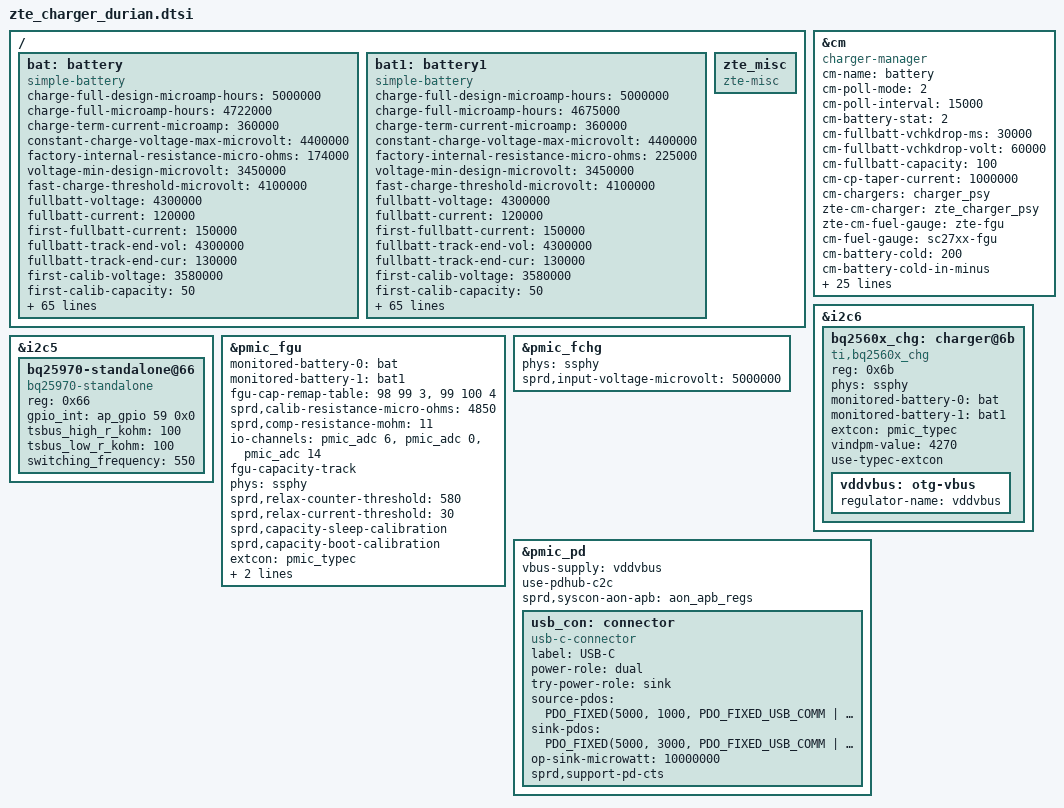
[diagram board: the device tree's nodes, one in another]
#include <dt-bindings/usb/pd.h>


/ {
	bat: battery {
		compatible = "simple-battery";
		status = "okay";
		charge-full-design-microamp-hours = <5000000>;
		/*Minimum Capacity 4870*0.9 = 4383 4870*0.94 = 4558 4870*0.95 = 4626 4870*0.96 = 4675,4870*0.98 = 4772  we use *0.98 */
		charge-full-microamp-hours = <4772000>;
		charge-term-current-microamp = <420000>;
		constant-charge-voltage-max-microvolt = <4400000>;
		factory-internal-resistance-micro-ohms = <225000>;
		voltage-min-design-microvolt = <3450000>;

		fast-charge-threshold-microvolt = <4100000>;
		fullbatt-voltage = <4300000>;
		fullbatt-current = <120000>;
		first-fullbatt-current = <150000>;
		fullbatt-track-end-vol = <4295000>;
		fullbatt-track-end-cur = <130000>;
		first-calib-voltage = <3580000>;
		first-calib-capacity = <50>;

		ir-cv-offset-microvolt = <100000>;
		ir-rc-micro-ohms = <20000>;
		ir-us-upper-limit-microvolt = <4500000>;

		batt-id-list = <300 10 390 20>;  /* kohm, scud / ningde / tianmao /guanyu*/
		ocv-capacity-celsius = <20>;
		ocv-capacity-table-0 = <4374000 100>, <4308000 95>, <4250000 90>,
					<4193000 85>, <4139000 80>, <4086000 75>,
					<4037000 70>, <3992000 65>, <3951000 60>,
					<3896000 55>, <3860000 50>, <3836000 45>,
					<3814000 40>, <3797000 35>, <3784000 30>,
					<3767000 25>, <3749000 20>, <3726000 15>,
					<3697000 10>, <3683000 5>, <3400000 0>;
		/* NTC 100k, Vref 1850mV, R pull-up 110K, R pull-down 1000k */
		voltage-temp-table = <1568441 750>, <1534549 800>, <1515014 850>,
					<1475819 900>, <1402274 950>, <1334550 1000>,
					<1222195 1050>, <1131821 1100>, <1035662 1150>,
					<936426 1200>, <837104 1250>, <740441 1300>,
					<648801 1350>, <563916 1400>, <486937 1450>,
					<418193 1500>, <357806 1550>, <305304 1600>,
					<260067 1650>, <221438 1700>, <188468 1750>;
		capacity-temp-table = <25 100>, <10 100>, <0 97>, <(-10) 89>, <(-20) 57>;
		resistance-temp-table = <25 100>, <10 332>, <0 507>, <(-10) 569>, <(-20) 675>;
		charge-sdp-current-microamp = <700000 500000>;
		charge-dcp-current-microamp = <2000000 3000000>;
		charge-cdp-current-microamp = <1500000 1500000>;
		charge-unknown-current-microamp = <1000000 1000000>;
		charge-fchg-current-microamp = <3400000 2000000>;
		charge-flash-current-microamp = <3400000 2700000>;

		cap-calib-energy-density-ocv-table = <3350000 3800000>, <4150000 4350000>;
		cap-track-energy-density-ocv-table = <3400000 3722000>;

		dcp-jeita-temp-table = <1000 1030 0 4400000>,
					<1050 1080 1400000 4400000>,
					<1100 1180 1400000 4400000>,
					<1450 1420 3400000 4400000>,
					<1550 1520 2400000 4100000>;
		sdp-jeita-temp-table = <1000 1030 0 4400000>,
					<1050 1080 1400000 4400000>,
					<1100 1180 1400000 4400000>,
					<1450 1420 3400000 4400000>,
					<1550 1520 2400000 4100000>;
		cdp-jeita-temp-table = <1000 1030 0 4400000>,
					<1050 1080 1400000 4400000>,
					<1100 1180 1400000 4400000>,
					<1450 1420 3400000 4400000>,
					<1550 1520 2400000 4100000>;
		unknown-jeita-temp-table = <1000 1030 0 4400000>,
					<1050 1080 1400000 4400000>,
					<1100 1180 1400000 4400000>,
					<1450 1420 3400000 4400000>,
					<1550 1520 2400000 4100000>;
		fchg-jeita-temp-table = <1000 1030 0 4400000>,
					<1050 1080 1400000 4400000>,
					<1100 1180 1400000 4400000>,
					<1450 1420 3400000 4400000>,
					<1550 1520 2400000 4100000>;
		flash-jeita-temp-table = <1000 1030 0 4400000>,
					<1050 1080 1400000 4400000>,
					<1100 1180 1400000 4400000>,
					<1450 1420 3400000 4400000>,
					<1550 1520 2400000 4100000>;
	};

	bat1: battery1 {
		compatible = "simple-battery";
		status = "okay";
		charge-full-design-microamp-hours = <5000000>;
		/*Minimum Capacity 4870*0.9 = 4383 4870*0.94 = 4558 4870*0.95 = 4626 4870*0.96 = 4675,4870*0.98 = 4772  we use *0.98 */
		charge-full-microamp-hours = <4772000>;
		charge-term-current-microamp = <420000>;
		constant-charge-voltage-max-microvolt = <4400000>;
		factory-internal-resistance-micro-ohms = <225000>;
		voltage-min-design-microvolt = <3450000>;

		fast-charge-threshold-microvolt = <4100000>;
		fullbatt-voltage = <4300000>;
		fullbatt-current = <120000>;
		first-fullbatt-current = <150000>;
		fullbatt-track-end-vol = <4295000>;
		fullbatt-track-end-cur = <130000>;
		first-calib-voltage = <3580000>;
		first-calib-capacity = <50>;

		ir-cv-offset-microvolt = <100000>;
		ir-rc-micro-ohms = <20000>;
		ir-us-upper-limit-microvolt = <4500000>;

		batt-id-list = <300 10 390 20>;  /* kohm, scud / ningde / tianmao /guanyu*/
		ocv-capacity-celsius = <20>;
		ocv-capacity-table-0 = <4374000 100>, <4308000 95>, <4250000 90>,
					<4193000 85>, <4139000 80>, <4086000 75>,
					<4037000 70>, <3992000 65>, <3951000 60>,
					<3896000 55>, <3860000 50>, <3836000 45>,
					<3814000 40>, <3797000 35>, <3784000 30>,
					<3767000 25>, <3749000 20>, <3726000 15>,
					<3697000 10>, <3683000 5>, <3400000 0>;
		/* NTC 100k, Vref 1850mV, R pull-up 110K, R pull-down 1000k */
		voltage-temp-table = <1568441 750>, <1534549 800>, <1515014 850>,
					<1475819 900>, <1402274 950>, <1334550 1000>,
					<1222195 1050>, <1131821 1100>, <1035662 1150>,
					<936426 1200>, <837104 1250>, <740441 1300>,
					<648801 1350>, <563916 1400>, <486937 1450>,
					<418193 1500>, <357806 1550>, <305304 1600>,
					<260067 1650>, <221438 1700>, <188468 1750>;
		capacity-temp-table = <25 100>, <10 100>, <0 97>, <(-10) 89>, <(-20) 57>;
		resistance-temp-table = <25 100>, <10 332>, <0 507>, <(-10) 569>, <(-20) 675>;
		charge-sdp-current-microamp = <700000 500000>;
		charge-dcp-current-microamp = <2000000 3000000>;
		charge-cdp-current-microamp = <1500000 1500000>;
		charge-unknown-current-microamp = <1000000 1000000>;
		charge-fchg-current-microamp = <3400000 2000000>;
		charge-flash-current-microamp = <3400000 2700000>;

		cap-calib-energy-density-ocv-table = <3350000 3800000>, <4150000 4350000>;
		cap-track-energy-density-ocv-table = <3400000 3722000>;

		dcp-jeita-temp-table = <1000 1030 0 4400000>,
					<1050 1080 1400000 4400000>,
					<1100 1180 1400000 4400000>,
					<1450 1420 3400000 4400000>,
					<1550 1520 2400000 4100000>;
		sdp-jeita-temp-table = <1000 1030 0 4400000>,
					<1050 1080 1400000 4400000>,
					<1100 1180 1400000 4400000>,
					<1450 1420 3400000 4400000>,
					<1550 1520 2400000 4100000>;
		cdp-jeita-temp-table = <1000 1030 0 4400000>,
					<1050 1080 1400000 4400000>,
					<1100 1180 1400000 4400000>,
					<1450 1420 3400000 4400000>,
					<1550 1520 2400000 4100000>;
		unknown-jeita-temp-table = <1000 1030 0 4400000>,
					<1050 1080 1400000 4400000>,
					<1100 1180 1400000 4400000>,
					<1450 1420 3400000 4400000>,
					<1550 1520 2400000 4100000>;
		fchg-jeita-temp-table = <1000 1030 0 4400000>,
					<1050 1080 1400000 4400000>,
					<1100 1180 1400000 4400000>,
					<1450 1420 3400000 4400000>,
					<1550 1520 2400000 4100000>;
		flash-jeita-temp-table = <1000 1030 0 4400000>,
					<1050 1080 1400000 4400000>,
					<1100 1180 1400000 4400000>,
					<1450 1420 3400000 4400000>,
					<1550 1520 2400000 4100000>;
	};




};

&bat {
	compatible = "simple-battery";
	status = "okay";
	charge-full-design-microamp-hours = <5000000>;
	/*Minimum Capacity 4870*0.9 = 4383 4870*0.94 = 4558 4870*0.95 = 4626 4870*0.96 = 4675,4870*0.98 = 4772  we use *0.98 */
	charge-full-microamp-hours = <4722000>;
	charge-term-current-microamp = <360000>;
	constant-charge-voltage-max-microvolt = <4400000>;
	factory-internal-resistance-micro-ohms = <174000>;
	voltage-min-design-microvolt = <3450000>;

	fast-charge-threshold-microvolt = <4100000>;
	fullbatt-voltage = <4300000>;
	fullbatt-current = <120000>;
	first-fullbatt-current = <150000>;
	fullbatt-track-end-vol = <4300000>;
	fullbatt-track-end-cur = <130000>;
	first-calib-voltage = <3580000>;
	first-calib-capacity = <50>;

	ir-cv-offset-microvolt = <100000>;
	ir-rc-micro-ohms = <20000>;
	ir-us-upper-limit-microvolt = <4500000>;

	batt-id-list = <180 51>;  /* kohm, tianmao/scud */
	ocv-capacity-celsius = <25>;
	ocv-capacity-table-0 = <4323000 100>, <4262000 95>, <4206000 90>,
				<4152000 85>, <4100000 80>, <4052000 75>,
				<4006000 70>, <3966000 65>, <3916000 60>,
				<3869000 55>, <3841000 50>, <3820000 45>,
				<3802000 40>, <3788000 35>, <3773000 30>,
				<3754000 25>, <3737000 20>, <3712000 15>,
				<3686000 10>, <3672000 5>, <3400000 0>;

	/* NTC 100k, Vref 1850mV, R pull-up 110K, R pull-down 1000k */
	voltage-temp-table = <1568441 750>, <1534549 800>, <1515014 850>,
				<1475819 900>, <1402274 950>, <1334550 1000>,
				<1222195 1050>, <1131821 1100>, <1035662 1150>,
				<936426 1200>, <837104 1250>, <740441 1300>,
				<648801 1350>, <563916 1400>, <486937 1450>,
				<418193 1500>, <357806 1550>, <305304 1600>,
				<260067 1650>, <221438 1700>, <188468 1750>;
	capacity-temp-table = <25 100>, <10 100>, <0 97>, <(-10) 90>, <(-20) 65>;
	resistance-temp-table = <25 100>, <10 195>, <0 610>, <(-10) 695>, <(-20) 809>;

	charge-sdp-current-microamp = <700000 500000>;
	charge-dcp-current-microamp = <4800000 2000000>;
	charge-cdp-current-microamp = <4800000 1500000>;
	charge-unknown-current-microamp = <1000000 1000000>;
	charge-fchg-current-microamp = <4800000 2000000>;
	charge-flash-current-microamp = <4800000 2000000>;

	cap-calib-energy-density-ocv-table = <3350000 3800000>, <4150000 4350000>;
	cap-track-energy-density-ocv-table = <3400000 3722000>;

	dcp-jeita-temp-table = <1000 1030 0 4400000>,
				<1100 1130 1461000 4400000>,
				<1150 1180 4800000 4400000>,
				<1450 1420 4800000 4400000>,
				<1550 1560 2435000 4100000>;
	sdp-jeita-temp-table = <1000 1030 0 4400000>,
				<1100 1130 1461000 4400000>,
				<1150 1180 4800000 4400000>,
				<1450 1420 4800000 4400000>,
				<1550 1560 2435000 4100000>;
	cdp-jeita-temp-table = <1000 1030 0 4400000>,
				<1100 1130 1461000 4400000>,
				<1150 1180 4800000 4400000>,
				<1450 1420 4800000 4400000>,
				<1550 1560 2435000 4100000>;
	unknown-jeita-temp-table = <1000 1030 0 4400000>,
				<1100 1130 1461000 4400000>,
				<1150 1180 4800000 4400000>,
				<1450 1420 4800000 4400000>,
				<1550 1560 2435000 4100000>;

	fchg-jeita-temp-table = <1000 1030 0 4400000>,
				<1100 1130 1461000 4400000>,
				<1150 1180 4800000 4400000>,
				<1450 1420 4800000 4400000>,
				<1550 1560 2435000 4100000>;
	flash-jeita-temp-table = <1000 1030 0 4400000>,
				<1100 1130 1461000 4400000>,
				<1150 1180 4800000 4400000>,
				<1450 1420 4800000 4400000>,
				<1550 1560 2435000 4100000>;
};

&bat1 {
	compatible = "simple-battery";
	status = "okay";
	charge-full-design-microamp-hours = <5000000>;
	/*Minimum Capacity 4870*0.9 = 4383 4870*0.94 = 4558 4870*0.95 = 4626 4870*0.96 = 4675,4870*0.98 = 4772  we use *0.96 */
	charge-full-microamp-hours = <4675000>;
	charge-term-current-microamp = <360000>;
	constant-charge-voltage-max-microvolt = <4400000>;
	factory-internal-resistance-micro-ohms = <225000>;
	voltage-min-design-microvolt = <3450000>;

	fast-charge-threshold-microvolt = <4100000>;
	fullbatt-voltage = <4300000>;
	fullbatt-current = <120000>;
	first-fullbatt-current = <150000>;
	fullbatt-track-end-vol = <4300000>;
	fullbatt-track-end-cur = <130000>;
	first-calib-voltage = <3580000>;
	first-calib-capacity = <50>;

	ir-cv-offset-microvolt = <100000>;
	ir-rc-micro-ohms = <20000>;
	ir-us-upper-limit-microvolt = <4500000>;

	batt-id-list = <180 51>;  /* kohm, tianmao/scud */
	ocv-capacity-celsius = <25>;
	ocv-capacity-table-0 = <4395000 100>, <4338000 95>, <4279000 90>,
				<4222000 85>, <4166000 80>, <4111000 75>,
				<4061000 70>, <4003000 65>, <3965000 60>,
				<3910000 55>, <3868000 50>, <3841000 45>,
				<3819000 40>, <3801000 35>, <3786000 30>,
				<3767000 25>, <3747000 20>, <3722000 15>,
				<3693000 10>, <3683000 5>, <3400000 0>;

	/* NTC 100k, Vref 1850mV, R pull-up 110K, R pull-down 1000k */
	voltage-temp-table = <1568441 750>, <1534549 800>, <1515014 850>,
				<1475819 900>, <1402274 950>, <1334550 1000>,
				<1222195 1050>, <1131821 1100>, <1035662 1150>,
				<936426 1200>, <837104 1250>, <740441 1300>,
				<648801 1350>, <563916 1400>, <486937 1450>,
				<418193 1500>, <357806 1550>, <305304 1600>,
				<260067 1650>, <221438 1700>, <188468 1750>;
	capacity-temp-table = <25 100>, <10 100>, <0 97>, <(-10) 95>, <(-20) 87>;
	resistance-temp-table = <25 100>, <10 139>, <0 431>, <(-10) 737>, <(-20) 976>;

	charge-sdp-current-microamp = <700000 500000>;
	charge-dcp-current-microamp = <4800000 2000000>;
	charge-cdp-current-microamp = <4800000 1500000>;
	charge-unknown-current-microamp = <1000000 1000000>;
	charge-fchg-current-microamp = <4800000 2000000>;
	charge-flash-current-microamp = <4800000 2000000>;

	cap-calib-energy-density-ocv-table = <3350000 3800000>, <4150000 4350000>;
	cap-track-energy-density-ocv-table = <3400000 3722000>;

	dcp-jeita-temp-table = <1000 1030 0 4400000>,
				<1100 1130 1461000 4400000>,
				<1150 1180 4800000 4400000>,
				<1450 1420 4800000 4400000>,
				<1550 1560 2435000 4100000>;
	sdp-jeita-temp-table = <1000 1030 0 4400000>,
				<1100 1130 1461000 4400000>,
				<1150 1180 4800000 4400000>,
				<1450 1420 4800000 4400000>,
				<1550 1560 2435000 4100000>;
	cdp-jeita-temp-table = <1000 1030 0 4400000>,
				<1100 1130 1461000 4400000>,
				<1150 1180 4800000 4400000>,
				<1450 1420 4800000 4400000>,
				<1550 1560 2435000 4100000>;
	unknown-jeita-temp-table = <1000 1030 0 4400000>,
				<1100 1130 1461000 4400000>,
				<1150 1180 4800000 4400000>,
				<1450 1420 4800000 4400000>,
				<1550 1560 2435000 4100000>;

	fchg-jeita-temp-table = <1000 1030 0 4400000>,
				<1100 1130 1461000 4400000>,
				<1150 1180 4800000 4400000>,
				<1450 1420 4800000 4400000>,
				<1550 1560 2435000 4100000>;
	flash-jeita-temp-table = <1000 1030 0 4400000>,
				<1100 1130 1461000 4400000>,
				<1150 1180 4800000 4400000>,
				<1450 1420 4800000 4400000>,
				<1550 1560 2435000 4100000>;
};

&cm {
	compatible = "charger-manager";
	status = "okay";
	cm-name = "battery";
	cm-poll-mode = <2>;
	cm-poll-interval = <15000>;
	cm-battery-stat = <2>;

	cm-fullbatt-vchkdrop-ms = <30000>;
	cm-fullbatt-vchkdrop-volt = <60000>;
	cm-fullbatt-capacity = <100>;
	/*Charge pump target charge current*/
	cm-cp-taper-current = <1000000>;

	cm-chargers = "charger_psy";
	zte-cm-charger = "zte_charger_psy";
	zte-cm-fuel-gauge = "zte-fgu";

	cm-fuel-gauge = "sc27xx-fgu";

	/* in deci centigrade */
	cm-battery-cold = <200>;
	cm-battery-cold-in-minus;
	cm-battery-hot = <800>;
	cm-battery-temp-diff = <100>;

	/* Allow charging for 6hr */
	cm-charging-max = <21600000>;
	/* recovery charging after stop charging 45min */
	cm-discharging-max = <2700000>;

	/* the interval to feed charger watchdog */
	cm-wdt-interval = <60>;

	/* drop voltage in microVolts to allow shutdown */
	cm-shutdown-voltage = <3100000>;

	/* when 99% of the time is exceeded, it will be forced to 100% */
	cm-tickle-time-out = <1500>;

	/* how much time to allow capacity change */
	cm-one-cap-time = <30>;

	/* because kernel not load thermal-gerneric-adc.ko in charger mode, then battery uevent can't broadcast to ztecharger */
	/* cm-thermal-zone = "board-thmzone"; */

	/* when the safe charging voltage is exceeded, stop charging */
	cm-charge-voltage-max = <6500000>;
	cm-fast-charge-voltage-max = <10500000>;
	cm-flash-charge-voltage-max = <12000000>;
	/* drop voltage in microVolts to restart charging */
	cm-charge-voltage-drop = <700000>;
	cm-fast-charge-voltage-drop = <700000>;
	cm-flash-charge-voltage-drop = <1000000>;

	/* sprd_fchg parameter */
	sprd,support-fchg;
	sprd,support-pd-pps;
	sprd,pd-fixed-max-microwatt = <22500000>;

	monitored-battery-0 = <&bat>;
	monitored-battery-1 = <&bat1>;
	cm-capacity-track;
	cm-keep-awake;

	phys = <&ssphy>;
	pd-extcon-enable;
	extcon = <&pmic_typec>, <&pmic_pd>;
	use-typec-extcon;
};

/ {
	zte_misc: zte_misc {
		status = "okay";
		compatible = "zte-misc";
	};
};

&i2c6 {
	#address-cells = <1>;
	#size-cells = <0>;

	status = "okay";
	bq2560x_chg: charger@6b {
		compatible = "ti,bq2560x_chg";
		reg = <0x6b>;
		phys = <&ssphy>;
		monitored-battery-0 = <&bat>;
		monitored-battery-1 = <&bat1>;
		extcon = <&pmic_typec>;
		vindpm-value = <4270>;
		use-typec-extcon;
		vddvbus:otg-vbus {
			regulator-name = "vddvbus";
		};
	};
};


&i2c5 {
	status = "okay";
	bq25970-standalone@66 {
		compatible = "bq25970-standalone";
		status = "okay";
		reg = <0x66>;
		gpio_int = <&ap_gpio 59 0x0>;
		tsbus_high_r_kohm = <100>;
		tsbus_low_r_kohm = <100>;
		switching_frequency = <550>;
	};
};

&pmic_fgu {
	monitored-battery-0 = <&bat>;
	monitored-battery-1 = <&bat1>;
	fgu-cap-remap-table = <98 99 3>, <99 100 4>;
	sprd,calib-resistance-micro-ohms = <4850>;
	sprd,comp-resistance-mohm = <11>;
	io-channels = <&pmic_adc 6>, <&pmic_adc 0>, <&pmic_adc 14>;
	io-channel-names = "adc-batt-id", "bat-temp", "charge-vol";
	fgu-capacity-track;
	phys = <&ssphy>;

	sprd,relax-counter-threshold = <580>;
	sprd,relax-current-threshold = <30>;
	sprd,capacity-sleep-calibration;

	sprd,capacity-boot-calibration;
	extcon = <&pmic_typec>;
	sprd,zte-low-temp-algo;
	use-typec-extcon;
};

&pmic_fchg {
	status = "okay";
	phys = <&ssphy>;
	sprd,input-voltage-microvolt = <5000000>;
};

&pmic_pd {
	status = "okay";
	vbus-supply = <&vddvbus>;
	use-pdhub-c2c;
	sprd,syscon-aon-apb = <&aon_apb_regs>;
	usb_con: connector {
		compatible = "usb-c-connector";
		label = "USB-C";
		power-role = "dual";
		try-power-role = "sink";
		source-pdos = <PDO_FIXED(5000, 1000, PDO_FIXED_USB_COMM | PDO_FIXED_SUSPEND |
			                 PDO_FIXED_DUAL_ROLE | PDO_FIXED_DATA_SWAP)>;
		sink-pdos = <PDO_FIXED(5000, 3000, PDO_FIXED_USB_COMM | PDO_FIXED_DUAL_ROLE |
				       PDO_FIXED_DATA_SWAP)
			     PDO_PPS_APDO(3300, 11000, 6000)>;
		op-sink-microwatt = <10000000>;

		sprd,support-pd-cts;
	};
};

#include "../bat_setting/battery_protect_policy_080509200178.dtsi"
